# iND83213A register map
Vendor: Indiemicro; Series: Rugby; File version: 1.0
CPU: CM0 r0p1, selectable endian, no MPU, no FPU, 4 interrupt priority bits
Registers are 32-bit, read-write, no defined reset value unless marked. A register's access mark holds for its fields unless they carry their own. Offsets are from the block's base; [hi:lo] are bit positions; {n}, {i} and the like mark numbered series.

## SYSCTRLA — System configuration and retention memory
Base 0x50013000; register names take the prefix SYSCTRLA_
0x00 RETAIN1 — Retained data 1
  [7:0] RETAIN1 — Firmware scratch register 1 (0x1). Contents retained in Hibernate mode - but lost after any hard or soft reset.
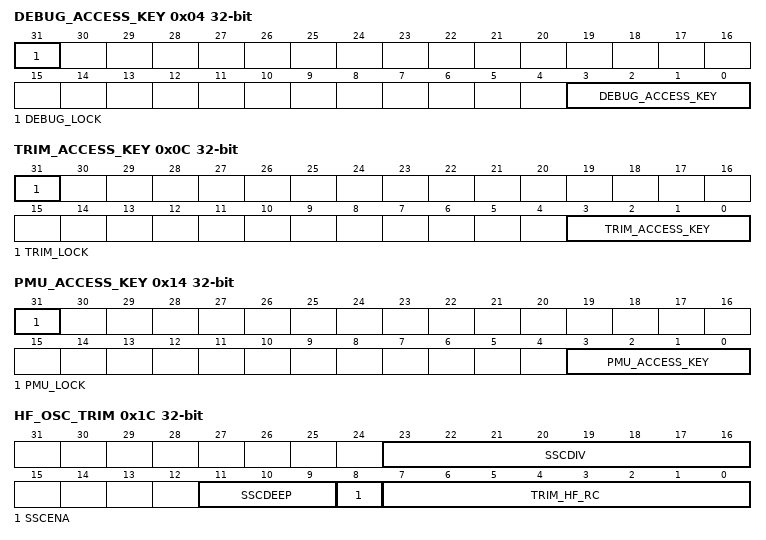
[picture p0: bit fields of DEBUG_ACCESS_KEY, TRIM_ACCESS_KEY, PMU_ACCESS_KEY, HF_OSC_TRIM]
0x04 DEBUG_ACCESS_KEY
  [31] DEBUG_LOCK — Set Only bit. Set this bit to lock DEBUG_CODE bits.
  [3:0] DEBUG_ACCESS_KEY — Write the value 0x5 to this register to enable debug options. Write any other value to disable the debug options.
0x08 DEBUG_ACCESS_ENABLED
  [0] DEBUG_ACCESS_ENABLED ro — A status flag that is set when debug access is enabled
0x0C TRIM_ACCESS_KEY
  [31] TRIM_LOCK — Set Only bit. Write 1 to this bit to lock TRIM_CODE bits.
  [3:0] TRIM_ACCESS_KEY — Write the value 0xe to this register to enable 'trim access' (which allows write access to various trim settings and production test options). Write any other value to disable trim access.
0x10 TRIM_ACCESS_ENABLED
  [0] TRIM_ACCESS_ENABLED ro — A status flag that is set when trim access is enabled
0x14 PMU_ACCESS_KEY — PMU configure access key
  [31] PMU_LOCK — Set Only bit. Set this bit to lock PMU_CODE bits.
  [3:0] PMU_ACCESS_KEY — Write the value 0xA to this register to enable 1v5 domain at hibernate. Write any other value to disable the 1v5 domain at hibernate.
0x18 PMU_ACCESS_ENABLED — PMU configure access enabled
  [0] PMU_ACCESS_ENABLED ro — A status flag that is set when pmu access is enabled
0x1C HF_OSC_TRIM — Trim controls for the high frequency (16MHz) oscillator
  [23:16] SSCDIV — SSC Clock Divider. SSC Freq = SYS_FREQ/[(SSC_DIV+1)*(SSC_DEEP+1)*4].
  [11:9] SSCDEEP — SSC Depth Configuration.
  [8] SSCENA — SSC Enable.
  [7:0] TRIM_HF_RC — High Frequency RC Oscillator trim. TRIM bits will be changed if SSC is enabled. Reload the trim bits from Flash if SSC is disabled while the change has happened. Following value only used as a reference: 0xa: freq=26.08Mhz 0x80: freq=9.62Mhz 0xfa: freq=5.94Mhz
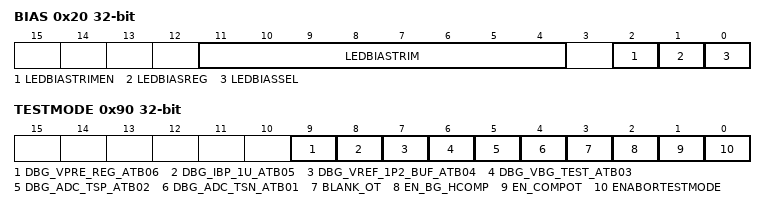
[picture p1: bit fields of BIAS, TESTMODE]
0x20 BIAS — Bias Control
  [11:4] LEDBIASTRIM — LED bias current trim. Each code is about 50nA step.
  [2] LEDBIASTRIMEN — LED bias trim eanble.
  [1] LEDBIASREG — High Voltage LED bias select register. If LED_BIAS_SEL is set, then LED_BIAS_REG allows override access to the LED BIAS signal.
  [0] LEDBIASSEL — High Voltage LED bias select. 0x0: The LED Bias is enabled and disabled by the pmu hardware state machine by default. 0x1: The value of the LED_BIAS_REG field is what is used to drive the LED_BIAS signal. (override mode)
{0x24+4i} TRIMLED{i} (i=0..23) — High Voltage LED trim
  [24:16] TRIM{i} — LED trim (100uA step).
0x84 TRIMVFW — VFW Current Trim
  [7:0] TRIMVFW — PN Forward Voltage Current trim (10uA step).
0x88 NAME — ASIC name
  [31:0] NAME ro — ASIC name. A read from this register will return the ASIC name
0x8C REV — Silicon Revision
  [15:0] REV ro — Silicon Revision. A read from this register will return the ASCII silicon revision (e.g. ASCII C0 is 0x4330)
0x90 TESTMODE — Testmode Enable
  [9] DBG_VPRE_REG_ATB06 — EN test VPRE_REG. MUX VPRE_REG to GPIO7
  [8] DBG_IBP_1U_ATB05 — EN test IBP_1U. MUX IBP_1U(current) to GPIO7
  [7] DBG_VREF_1P2_BUF_ATB04 — EN test VREF_1P2_BUF. MUX VREF_1P2_BUF to GPIO7
  [6] DBG_VBG_TEST_ATB03 — EN test VBG_TEST. MUX VBG_TEST to GPIO7
  [5] DBG_ADC_TSP_ATB02 — EN test ADC_TSP. Mux ADC_TSP to GPIO8.
  [4] DBG_ADC_TSN_ATB01 — EN test ADC_TSN. Mux ADC_TSN to GPIO7.
  [3] BLANK_OT — blanking the OT signal when the OT channel changes.
  [2] EN_BG_HCOMP — Enable the comparator of over temperature function.
  [1] EN_COMPOT — Enable the comparator of over temperature function.
  [0] ENABORTESTMODE — BOR Testmode Enable. 0x0: BOR Testmode Disabled: Reference Voltage for BOR is from Band Gap (Functional Mode) 0x1: BOR Testmode Enabled: Reference Voltage for BOR is from GPIO7 (Test Mode)
